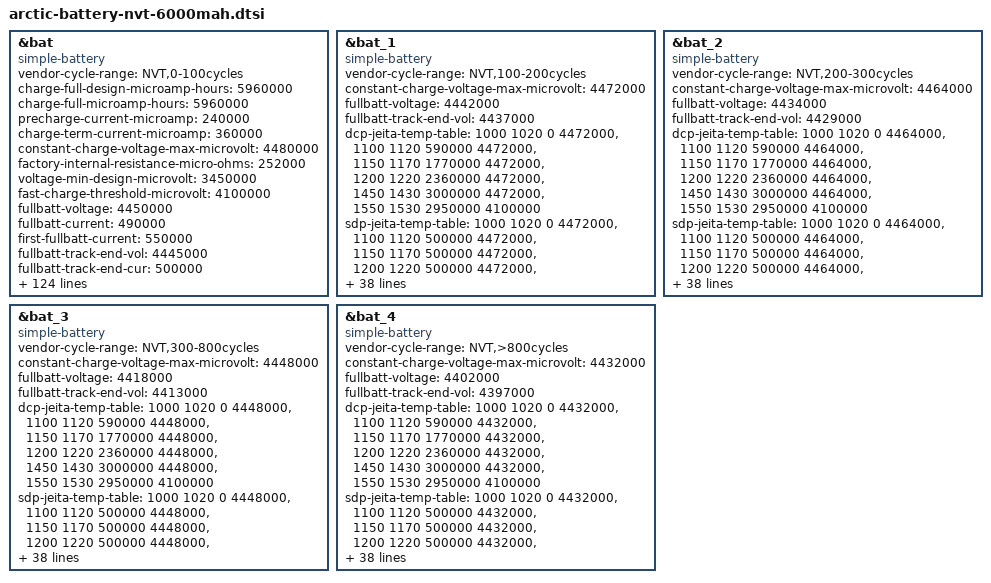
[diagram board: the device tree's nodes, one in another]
/* NVT aging 0--100 */
&bat {
	compatible = "simple-battery";
	status = "okay";
	vendor-cycle-range = "NVT,0-100cycles";
	charge-full-design-microamp-hours = <5960000>;
	charge-full-microamp-hours = <5960000>;
	precharge-current-microamp = <240000>;
	charge-term-current-microamp = <360000>;
	constant-charge-voltage-max-microvolt = <4480000>;
	factory-internal-resistance-micro-ohms = <252000>;
	voltage-min-design-microvolt = <3450000>;

	fast-charge-threshold-microvolt = <4100000>;
	fullbatt-voltage = <4450000>;
	fullbatt-current = <490000>;
	first-fullbatt-current = <550000>;
	fullbatt-track-end-vol = <4445000>;
	fullbatt-track-end-cur = <500000>;
	first-calib-voltage = <3580000>;
	first-calib-capacity = <50>;
	batt-ovp-threshold-microvolt = <4750000>;
	shutdown-voltage = <3150000>; //软件UVLO关机电压

	voltage-temp-table = <1119814 800>, <1007626 850>, <897107 900>,
				<791150 950>, <692012 1000>, <601214 1050>,
				<519546 1100>, <447188 1150>, <383853 1200>,
				<328947 1250>, <281696 1300>, <241249 1350>,
				<206756 1400>, <177412 1450>, <152480 1500>,
				<131307 1550>, <113324 1600>, <98032 1650>;

	temp-advance-fullcap-table = <50 100>, <25 100>, <10 100>, <0 100>,
		<(-10) 100>, <(-20) 100>;

	bcl-vbat-thres-celsius = <(-10)>, <0>, <10>, <25>, <45>;
	bcl-vbat-h-thres-0 = <3500>, <3400>;
	bcl-vbat-l-thres-0 = <3300>, <3200>;
	bcl-vbat-h-thres-1 = <3500>, <3400>;
	bcl-vbat-l-thres-1 = <3300>, <3200>;
	bcl-vbat-h-thres-2 = <3500>, <3400>;
	bcl-vbat-l-thres-2 = <3300>, <3200>;
	bcl-vbat-h-thres-3 = <3500>, <3400>;
	bcl-vbat-l-thres-3 = <3300>, <3200>;
	bcl-vbat-h-thres-4 = <3500>, <3400>;
	bcl-vbat-l-thres-4 = <3300>, <3200>;

	charge-sdp-current-microamp = <500000 500000>;
	charge-dcp-current-microamp = <2940000 1500000>;
	charge-cdp-current-microamp = <900000 900000>;
	charge-unknown-current-microamp = <1000000 1000000>;
	charge-fchg-current-microamp = <3000000 2000000>;
	charge-flash-current-microamp = <4900000 2700000>;
	charge-wl-bpp-current-microamp = <1000000 1000000>;
	charge-wl-epp-current-microamp = <2000000 1000000>;

	cap-calib-energy-density-ocv-table = <3400000 3690000>, <3890000 4480000>;

	dcp-jeita-temp-table = <1000 1020 0 4480000>, <1100 1120 590000 4480000>,
		<1150 1170 1770000 4480000>, <1200 1220 2360000 4480000>,
		<1450 1430 3000000 4480000>, <1550 1530 2950000 4100000>;
	sdp-jeita-temp-table = <1000 1020 0 4480000>, <1100 1120 500000 4480000>,
		<1150 1170 500000 4480000>, <1200 1220 500000 4480000>,
		<1450 1430 500000 4480000>, <1550 1530 500000 4100000>;
	cdp-jeita-temp-table = <1000 1020 0 4480000>, <1100 1120 590000 4480000>,
		<1150 1170 900000 4480000>, <1200 1220 900000 4480000>,
		<1450 1430 900000 4480000>, <1550 1530 900000 4100000>;
	unknown-jeita-temp-table = <1000 1020 0 4480000>, <1100 1120 590000 4480000>,
		<1150 1170 1000000 4480000>, <1200 1220 1000000 4480000>,
		<1450 1430 1000000 4480000>, <1550 1530 1000000 4100000>;
	fchg-jeita-temp-table = <1000 1020 0 4480000>, <1100 1120 590000 4480000>,
		<1150 1170 1770000 4480000>, <1200 1220 2360000 4480000>,
		<1450 1430 3000000 4480000>, <1550 1530 2950000 4100000>;
	flash-jeita-temp-table = <1000 1020 0 4480000>, <1100 1120 590000 4480000>,
		<1150 1170 1770000 4480000>, <1200 1220 2360000 4480000>,
		<1450 1430 3000000 4480000>, <1550 1530 2950000 4100000>;
	wl-bpp-jeita-temp-table = <1000 1020 0 4480000>, <1100 1120 500000 4480000>,
		<1150 1170 500000 4480000>, <1200 1220 500000 4480000>,
		<1450 1430 1000000 4480000>, <1550 1530 500000 4100000>;
	wl-epp-jeita-temp-table = <1000 1020 0 4480000>, <1100 1120 500000 4480000>,
		<1150 1170 500000 4480000>, <1200 1220 500000 4480000>,
		<1450 1430 2000000 4480000>, <1550 1530 500000 4100000>;


	bat-temp = <(-20)>, <(-10)>, <0>, <10>, <25>, <45>;

	/* temp-fcc */
	temp-fcc-fcc = <5344000>, <5537000>, <5769000>, <5883000>, <5960000>, <5931000>;

	/* temp-hc */
	temp-hc-hc = <20>, <20>, <20>, <10>, <10>, <10>;

	/* temp-zero-point-voltage */
	temp-zpvol-zpvol = <3430000>, <3430000>, <3430000>, <3450000>, <3450000>, <3450000>;
	/* temp-abs-zero-point-voltage */
	temp-abs-zpvol-zpvol = <3425000>, <3425000>, <3425000>, <3445000>, <3445000>, <3445000>;
	/* temp-bat-voltage */
	temp-batvol-batvol = <3570000>, <3570000>, <3570000>, <3580000>, <3580000>, <3580000>;

	/* cap-temp-ocv */
	cap-temp-ocv-cap = <100>, <99>, <98>, <97>, <96>, <95>, <94>, <93>, <92>, <91>, <90>,
			<89>, <88>, <87>, <86>, <85>, <84>, <83>, <82>, <81>, <80>,
			<79>, <78>, <77>, <76>, <75>, <74>, <73>, <72>, <71>, <70>,
			<69>, <68>, <67>, <66>, <65>, <64>, <63>, <62>, <61>, <60>,
			<59>, <58>, <57>, <56>, <55>, <54>, <53>, <52>, <51>, <50>,
			<49>, <48>, <47>, <46>, <45>, <44>, <43>, <42>, <41>, <40>,
			<39>, <38>, <37>, <36>, <35>, <34>, <33>, <32>, <31>, <30>,
			<29>, <28>, <27>, <26>, <25>, <24>, <23>, <22>, <21>, <20>,
			<19>, <18>, <17>, <16>, <15>, <14>, <13>, <12>, <11>, <10>,
			<9>, <8>, <7>, <6>, <5>, <4>, <3>, <2>, <1>, <0>;
	cap-temp-ocv-ocv = <
			/* -20 celsius */
			4428000 4394000 4369000 4350000 4332000 4317000 4302000 4288000 4274000 4261000
			4248000 4236000 4224000 4212000 4200000 4188000 4178000 4166000 4156000 4146000
			4136000 4126000 4118000 4108000 4098000 4090000 4080000 4072000 4062000 4054000
			4044000 4036000 4026000 4018000 4009000 4000000 3991000 3982000 3973000 3964000
			3956000 3946000 3938000 3929000 3920000 3912000 3904000 3896000 3888000 3880000
			3872000 3866000 3859000 3852000 3846000 3840000 3835000 3830000 3824000 3820000
			3815000 3811000 3807000 3804000 3801000 3798000 3796000 3793000 3791000 3789000
			3786000 3784000 3782000 3780000 3778000 3776000 3773000 3770000 3768000 3765000
			3762000 3758000 3756000 3752000 3748000 3742000 3737000 3732000 3725000 3717000
			3708000 3698000 3688000 3675000 3663000 3651000 3636000 3618000 3597000 3576000
			3556000
			/* -10 celsius */
			4432000 4401000 4377000 4358000 4342000 4328000 4314000 4300000 4286000 4272000
			4260000 4246000 4234000 4222000 4211000 4200000 4190000 4179000 4169000 4159000
			4149000 4140000 4131000 4121000 4112000 4102000 4093000 4084000 4074000 4065000
			4056000 4046000 4037000 4028000 4018000 4010000 4000000 3992000 3983000 3974000
			3965000 3956000 3947000 3938000 3928000 3919000 3910000 3900000 3891000 3882000
			3874000 3866000 3859000 3852000 3846000 3840000 3834000 3829000 3824000 3819000
			3815000 3810000 3806000 3803000 3800000 3796000 3794000 3791000 3789000 3787000
			3786000 3784000 3783000 3781000 3780000 3778000 3777000 3775000 3773000 3771000
			3769000 3766000 3763000 3760000 3756000 3751000 3746000 3740000 3732000 3723000
			3710000 3694000 3674000 3652000 3628000 3606000 3586000 3567000 3548000 3532000
			3518000
			/* 0 celsius */
			4428000 4398000 4376000 4358000 4341000 4326000 4312000 4298000 4284000 4272000
			4259000 4247000 4235000 4224000 4213000 4202000 4192000 4182000 4171000 4161000
			4151000 4141000 4130000 4120000 4110000 4099000 4089000 4079000 4069000 4059000
			4049000 4039000 4030000 4020000 4011000 4002000 3993000 3984000 3976000 3968000
			3960000 3951000 3942000 3934000 3925000 3914000 3904000 3893000 3883000 3872000
			3863000 3855000 3848000 3842000 3836000 3831000 3826000 3821000 3817000 3813000
			3809000 3805000 3802000 3798000 3796000 3792000 3790000 3788000 3786000 3784000
			3783000 3782000 3781000 3780000 3778000 3778000 3776000 3774000 3772000 3770000
			3768000 3764000 3760000 3755000 3750000 3743000 3735000 3725000 3712000 3693000
			3670000 3644000 3618000 3592000 3570000 3552000 3537000 3524000 3512000 3498000
			3479000
			/* 10 celsius */
			4445000 4414000 4390000 4369000 4352000 4336000 4322000 4308000 4294000 4282000
			4270000 4257000 4246000 4234000 4223000 4212000 4201000 4190000 4180000 4168000
			4158000 4147000 4136000 4126000 4115000 4104000 4094000 4082000 4072000 4062000
			4052000 4042000 4032000 4022000 4013000 4004000 3995000 3986000 3978000 3970000
			3961000 3954000 3945000 3937000 3929000 3920000 3911000 3900000 3887000 3875000
			3864000 3856000 3849000 3842000 3837000 3832000 3826000 3822000 3818000 3814000
			3810000 3806000 3803000 3800000 3797000 3794000 3792000 3789000 3787000 3786000
			3784000 3782000 3782000 3780000 3780000 3778000 3777000 3776000 3774000 3771000
			3767000 3763000 3758000 3754000 3750000 3745000 3739000 3731000 3720000 3708000
			3692000 3672000 3644000 3616000 3592000 3574000 3556000 3540000 3524000 3502000
			3462000
			/* 25 celsius */
			4441000 4411000 4386000 4366000 4349000 4334000 4319000 4306000 4292000 4280000
			4267000 4255000 4243000 4232000 4220000 4210000 4198000 4188000 4176000 4166000
			4154000 4143000 4132000 4121000 4110000 4100000 4088000 4078000 4068000 4058000
			4047000 4037000 4028000 4018000 4008000 4000000 3990000 3982000 3974000 3965000
			3957000 3949000 3942000 3934000 3926000 3918000 3908000 3896000 3882000 3870000
			3860000 3853000 3847000 3841000 3836000 3831000 3826000 3822000 3818000 3814000
			3810000 3807000 3804000 3801000 3798000 3796000 3793000 3791000 3790000 3788000
			3786000 3784000 3783000 3782000 3780000 3776000 3774000 3770000 3766000 3762000
			3758000 3754000 3752000 3748000 3744000 3740000 3733000 3726000 3720000 3712000
			3701000 3692000 3681000 3663000 3638000 3612000 3588000 3564000 3529000 3473000
			3400000
			/* 45 celsius */
			4434000 4406000 4381000 4361000 4344000 4328000 4312000 4300000 4286000 4274000
			4261000 4250000 4238000 4227000 4216000 4204000 4194000 4183000 4172000 4161000
			4150000 4140000 4128000 4118000 4106000 4096000 4086000 4074000 4064000 4054000
			4044000 4034000 4025000 4015000 4006000 3997000 3988000 3980000 3971000 3964000
			3956000 3948000 3940000 3932000 3924000 3916000 3908000 3895000 3881000 3869000
			3860000 3854000 3848000 3842000 3836000 3832000 3827000 3822000 3818000 3814000
			3810000 3807000 3803000 3800000 3797000 3794000 3792000 3789000 3787000 3785000
			3783000 3782000 3780000 3778000 3774000 3766000 3760000 3756000 3754000 3750000
			3746000 3742000 3738000 3736000 3732000 3726000 3720000 3714000 3706000 3700000
			3690000 3682000 3676000 3666000 3646000 3622000 3596000 3570000 3530000 3472000
			3400000
			>;


	/* cap-temp-resist */
	cap-temp-resist-cap = <100>, <99>, <98>, <97>, <96>, <95>, <94>, <93>, <92>, <91>, <90>,
			<89>, <88>, <87>, <86>, <85>, <84>, <83>, <82>, <81>, <80>,
			<79>, <78>, <77>, <76>, <75>, <74>, <73>, <72>, <71>, <70>,
			<69>, <68>, <67>, <66>, <65>, <64>, <63>, <62>, <61>, <60>,
			<59>, <58>, <57>, <56>, <55>, <54>, <53>, <52>, <51>, <50>,
			<49>, <48>, <47>, <46>, <45>, <44>, <43>, <42>, <41>, <40>,
			<39>, <38>, <37>, <36>, <35>, <34>, <33>, <32>, <31>, <30>,
			<29>, <28>, <27>, <26>, <25>, <24>, <23>, <22>, <21>, <20>,
			<19>, <18>, <17>, <16>, <15>, <14>, <13>, <12>, <11>, <10>,
			<9>, <8>, <7>, <6>, <5>, <4>, <3>, <2>, <1>, <0>;
	cap-temp-resist-resist = <
		  /* -20 celsius m o */
			684  684  718  724  724  724  720  715  712  708
			702  700  696  692  690  686  683  685  672  678
			676  674  672  668  668  670  670  671  670  670
			670  668  668  670  671  668  670  666  668  664
			664  665  664  661  656  662  660  658  656  656
			658  660  657  658  660  658  664  664  665  668
			672  677  682  685  691  690  698  705  712  720
			730  738  752  764  775  789  809  830  850  872
			890  914  944  978 1011 1052 1097 1146 1214 1302
			1420 1578 1806 2129 2573 2880 2880 2880 2880 2880
			2880
		  /* -10 celsius */
			349  349  358  366  369  370  369  368  366  364
			362  362  360  360  357  356  356  355  356  355
			354  355  355  354  354  355  355  355  358  358
			360  361  362  363  363  364  364  364  366  365
			364  364  362  360  357  354  350  345  340  337
			334  331  330  328  328  328  328  328  329  330
			330  331  332  334  334  336  337  338  340  344
			346  351  356  359  365  371  378  386  394  405
			416  430  445  462  482  508  538  575  620  676
			746  833  966 1227 1890 2674 2726 2726 2726 2726
			2740
		  /* 0 celsius */
			194  194  188  184  182  182  180  180  180  180
			180  178  178  179  180  180  180  180  180  180
			180  180  180  180  180  182  182  184  184  186
			186  188  189  190  191  193  194  196  198  200
			201  203  204  204  202  200  195  189  183  178
			174  172  170  168  168  168  168  168  170  169
			170  172  171  172  173  174  174  176  176  177
			179  180  182  184  186  189  192  196  199  202
			206  211  216  224  235  252  277  314  358  403
			440  469  504  574  750 1314 2437 2566 2580 2590
			2600
		  /* 10 celsius */
			116 116 116 114 112 112 112 112 112 112
			112 112 112 113 112 113 112 112 112 113
			112 112 113 112 114 114 114 114 114 116
			117 118 118 120 120 122 124 125 127 129
			130 132 134 136 138 139 138 133 125 118
			112 109 107 106 106 106 105 106 106 106
			106 106 107 108 108 108 108 109 110 110
			110 112 112 113 114 114 116 115 115 114
			114 113 113 114 116 118 122 128 137 153
			178 204 219 222 224 230 246 281 368 704
			2291
		  /* 25 celsius */
			81  81  80  80  79  79  78  78  80  79
			80  80  80  80  80  80  80  81  80  80
			80  80  80  80  80  82  81  82  82  83
			83  84  85  84  85  86  88  88  90  92
			93  94  96  98 100 102 102  97  88  82
			80  78  78  78  78  78  78  77  78  78
			78  78  78  80  80  80  81  82  82  82
			84  85  84  86  84  82  80  79  78  78
			78  78  79  80  80  80  80  82  82  83
			86  91  98 110 124 128 129 130 130 132
			144
		  /* 45 celsius */
			66 66 67 68 67 66 66 68 68 66
			68 68 67 68 68 68 68 68 68 68
			68 68 68 68 68 68 69 70 70 70
			70 71 71 71 71 72 73 73 74 75
			76 76 78 80 81 82 83 80 74 70
			70 68 68 68 68 68 68 68 68 68
			68 69 70 70 70 70 70 72 72 72
			74 74 75 76 72 68 68 68 68 70
			70 68 68 69 70 70 70 70 70 71
			71 74 75 76 80 85 86 86 84 86
			90
		>;
	cap-temp-resist-cycle = <300>, <600>;
	cap-temp-resist-ratio-0 = <
		  /* -20 celsius m o */
		  1030 1030 1030 1030 1030 1030 1030 1030 1030 1030 1040
		  1050 1050 1050 1060 1060 1060 1060 1060 1060 1060 1060
		  1060 1060 1060 1060 1060 1060 1060 1060 1060 1060 1060
		  1060 1060 1060 1060 1060 1060 1060 1060 1060 1060 1060
		  1060 1060 1060 1060 1060 1060 1060 1060 1060 1060 1060
		  1060 1060 1060 1060 1060 1060 1060 1060 1060 1050 1050
		  1050 1050 1050 1050 1050 1050 1050 1050 1050 1050 1050
		  1050 1050 1050 1050 1050 1050 1050 1050 1050 1050 1050
		  1050 1050 1050 1050 1050 1050 1050 1050 1050 1050 1050
		  1050 1050
		  /* -10 celsius */
		  1050 1050 1050 1050 1050 1050 1050 1050 1050 1050 1050
		  1050 1050 1050 1050 1050 1050 1050 1050 1050 1050 1050
		  1050 1050 1050 1050 1050 1050 1050 1050 1050 1050 1050
		  1050 1050 1050 1050 1050 1050 1050 1050 1050 1050 1050
		  1050 1050 1050 1050 1050 1050 1050 1050 1050 1050 1050
		  1050 1050 1050 1050 1050 1050 1050 1050 1050 1050 1050
		  1050 1050 1050 1050 1050 1050 1050 1050 1050 1050 1050
		  1050 1050 1050 1050 1050 1050 1050 1050 1050 1050 1050
		  1050 1050 1050 1050 1050 1050 1050 1050 1050 1050 1050
		  1050 1050
		  /* 0 celsius */
		  1160 1160 1160 1160 1160 1160 1160 1160 1170 1170 1170
		  1170 1170 1170 1170 1170 1170 1170 1170 1170 1170 1170
		  1170 1170 1170 1170 1170 1170 1170 1170 1170 1170 1170
		  1170 1170 1170 1180 1180 1180 1180 1180 1180 1180 1180
		  1180 1180 1190 1190 1190 1190 1190 1190 1190 1190 1190
		  1190 1190 1190 1190 1190 1190 1190 1190 1190 1190 1190
		  1190 1200 1200 1210 1220 1220 1220 1220 1220 1220 1230
		  1230 1230 1230 1230 1230 1230 1230 1230 1230 1230 1230
		  1230 1230 1230 1230 1250 1270 1290 1320 1350 1370 1400
		  1430 1430
		  /* 10 celsius */
		  1270 1270 1270 1270 1270 1270 1270 1270 1270 1280 1280
		  1280 1280 1290 1290 1290 1290 1290 1290 1290 1290 1290
		  1290 1300 1300 1300 1300 1300 1300 1300 1300 1300 1300
		  1300 1310 1310 1310 1310 1310 1310 1310 1310 1310 1310
		  1320 1320 1320 1320 1320 1320 1320 1320 1320 1320 1320
		  1320 1320 1330 1330 1330 1330 1330 1330 1330 1330 1330
		  1330 1330 1330 1330 1340 1340 1340 1340 1340 1340 1350
		  1360 1380 1400 1410 1430 1450 1470 1490 1500 1510 1520
		  1530 1530 1530 1530 1530 1530 1530 1530 1530 1530 1530
		  1530 1530
		  /* 25 celsius */
		  1110 1110 1110 1110 1110 1110 1110 1120 1120 1120 1130
		  1130 1140 1140 1140 1140 1140 1130 1130 1130 1130 1130
		  1130 1120 1120 1120 1120 1120 1120 1120 1120 1120 1120
		  1130 1130 1130 1130 1130 1140 1140 1140 1140 1140 1150
		  1150 1160 1160 1160 1160 1160 1160 1160 1160 1150 1150
		  1150 1150 1150 1160 1160 1160 1160 1160 1160 1150 1150
		  1150 1150 1150 1160 1160 1160 1160 1160 1160 1160 1160
		  1160 1160 1160 1160 1160 1160 1160 1160 1160 1150 1150
		  1150 1150 1150 1150 1150 1160 1160 1160 1160 1160 1160
		  1160 1160
		  /* 45 celsius */
		  1260 1260 1260 1260 1260 1260 1260 1270 1280 1290 1300
		  1300 1300 1300 1300 1300 1300 1300 1300 1300 1300 1300
		  1290 1290 1280 1270 1280 1290 1300 1310 1310 1310 1310
		  1310 1310 1310 1310 1310 1310 1310 1310 1310 1300 1290
		  1280 1270 1270 1270 1270 1270 1290 1290 1290 1290 1300
		  1310 1310 1310 1310 1310 1310 1310 1310 1300 1290 1290
		  1290 1290 1290 1300 1310 1310 1320 1320 1320 1320 1320
		  1320 1320 1320 1320 1320 1320 1320 1320 1320 1320 1310
		  1310 1310 1310 1310 1310 1310 1310 1320 1320 1320 1320
		  1320 1320
		>;

	cap-temp-resist-ratio-1 = <
		  /* -20 celsius m o */
		  1160 1160 1160 1160 1160 1160 1160 1160 1160 1170 1170
		  1180 1180 1190 1190 1190 1190 1200 1200 1210 1210 1210
		  1220 1220 1230 1230 1240 1250 1260 1270 1270 1270 1280
		  1290 1300 1310 1320 1340 1360 1380 1400 1400 1430 1460
		  1490 1520 1520 1520 1550 1590 1630 1660 1660 1690 1720
		  1750 1770 1770 1770 1770 1770 1770 1770 1770 1770 1770
		  1770 1770 1770 1770 1770 1770 1770 1770 1770 1770 1770
		  1770 1770 1770 1770 1770 1770 1770 1770 1770 1770 1770
		  1770 1770 1770 1770 1770 1770 1770 1770 1770 1770 1770
		  1770 1770
		  /* -10 celsius */
		  1180 1180 1180 1180 1180 1180 1180 1180 1170 1170 1170
		  1170 1170 1170 1170 1170 1170 1170 1170 1170 1170 1170
		  1170 1170 1170 1170 1170 1170 1170 1170 1170 1170 1170
		  1170 1170 1170 1170 1170 1170 1170 1170 1170 1170 1190
		  1190 1190 1190 1190 1200 1200 1200 1200 1200 1210 1210
		  1210 1210 1210 1210 1220 1240 1250 1270 1290 1290 1290
		  1290 1290 1290 1290 1300 1310 1320 1330 1340 1350 1350
		  1350 1370 1390 1410 1420 1440 1440 1460 1480 1500 1530
		  1550 1570 1590 1610 1620 1620 1620 1620 1620 1620 1620
		  1620 1620
		  /* 0 celsius */
		  1420 1420 1420 1420 1420 1420 1420 1420 1410 1410 1410
		  1410 1410 1410 1410 1410 1410 1410 1410 1410 1410 1410
		  1400 1400 1400 1400 1400 1400 1400 1400 1400 1400 1400
		  1400 1400 1400 1400 1400 1400 1400 1400 1400 1410 1410
		  1410 1410 1420 1420 1420 1420 1420 1420 1420 1420 1420
		  1420 1430 1430 1430 1430 1430 1430 1450 1450 1450 1450
		  1450 1450 1500 1500 1500 1500 1500 1500 1530 1530 1530
		  1530 1530 1530 1550 1550 1550 1550 1610 1610 1610 1610
		  1650 1700 1750 1800 1850 1900 1900 1900 1900 1900 1900
		  1900 1900
		  /* 10 celsius */
		  1400 1400 1400 1400 1400 1400 1400 1400 1400 1420 1420
		  1420 1420 1420 1420 1420 1420 1420 1420 1420 1420 1420
		  1420 1420 1420 1420 1420 1420 1410 1410 1410 1410 1410
		  1410 1410 1410 1410 1410 1410 1410 1410 1410 1410 1410
		  1410 1420 1420 1420 1420 1430 1430 1430 1430 1430 1420
		  1430 1430 1430 1430 1430 1430 1430 1430 1430 1430 1430
		  1430 1430 1430 1430 1470 1470 1470 1470 1470 1530 1530
		  1530 1530 1530 1590 1590 1590 1590 1630 1680 1710 1710
		  1780 1840 1900 1950 2000 2050 2100 2150 2200 2250 2250
		  2250 2250
		  /* 25 celsius */
		  1320 1320 1320 1320 1320 1320 1320 1320 1320 1320 1320
		  1320 1310 1310 1310 1310 1310 1310 1300 1300 1300 1300
		  1300 1290 1290 1290 1290 1290 1280 1280 1280 1280 1280
		  1280 1280 1280 1280 1280 1280 1280 1280 1280 1280 1290
		  1290 1300 1310 1310 1310 1310 1310 1310 1310 1310 1310
		  1310 1310 1310 1310 1310 1310 1310 1310 1310 1310 1310
		  1310 1310 1310 1310 1310 1310 1310 1320 1330 1340 1350
		  1350 1360 1360 1360 1360 1360 1370 1370 1370 1380 1390
		  1400 1410 1420 1430 1450 1460 1460 1460 1460 1460 1460
		  1460 1460
		  /* 45 celsius */
		  1298 1298 1298 1298 1298 1298 1298 1308 1318 1329 1339
		  1339 1339 1339 1339 1339 1339 1339 1339 1339 1339 1339
		  1329 1329 1318 1308 1318 1329 1339 1349 1349 1349 1349
		  1349 1349 1349 1349 1349 1349 1349 1349 1349 1339 1329
		  1318 1308 1308 1308 1308 1308 1329 1329 1329 1329 1339
		  1349 1349 1349 1349 1349 1349 1349 1349 1339 1329 1329
		  1329 1329 1329 1339 1349 1349 1360 1360 1360 1360 1360
		  1360 1360 1360 1360 1360 1360 1360 1360 1360 1360 1349
		  1349 1349 1349 1349 1349 1349 1349 1360 1360 1360 1360
		  1360 1360
		>;
};

/* NVT aging 100--200 */
&bat_1 {
	compatible = "simple-battery";
	status = "okay";
	vendor-cycle-range = "NVT,100-200cycles";
	constant-charge-voltage-max-microvolt = <4472000>;
	fullbatt-voltage = <4442000>;
	fullbatt-track-end-vol = <4437000>;

	dcp-jeita-temp-table = <1000 1020 0 4472000>, <1100 1120 590000 4472000>,
		<1150 1170 1770000 4472000>, <1200 1220 2360000 4472000>,
		<1450 1430 3000000 4472000>, <1550 1530 2950000 4100000>;
	sdp-jeita-temp-table = <1000 1020 0 4472000>, <1100 1120 500000 4472000>,
		<1150 1170 500000 4472000>, <1200 1220 500000 4472000>,
		<1450 1430 500000 4472000>, <1550 1530 500000 4100000>;
	cdp-jeita-temp-table = <1000 1020 0 4472000>, <1100 1120 590000 4472000>,
		<1150 1170 900000 4472000>, <1200 1220 900000 4472000>,
		<1450 1430 900000 4472000>, <1550 1530 900000 4100000>;
	unknown-jeita-temp-table = <1000 1020 0 4472000>, <1100 1120 590000 4472000>,
		<1150 1170 1000000 4472000>, <1200 1220 1000000 4472000>,
		<1450 1430 1000000 4472000>, <1550 1530 1000000 4100000>;
	fchg-jeita-temp-table = <1000 1020 0 4472000>, <1100 1120 590000 4472000>,
		<1150 1170 1770000 4472000>, <1200 1220 2360000 4472000>,
		<1450 1430 3000000 4472000>, <1550 1530 2950000 4100000>;
	flash-jeita-temp-table = <1000 1020 0 4472000>, <1100 1120 590000 4472000>,
		<1150 1170 1770000 4472000>, <1200 1220 2360000 4472000>,
		<1450 1430 3000000 4472000>, <1550 1530 2950000 4100000>;
	wl-bpp-jeita-temp-table = <1000 1020 0 4472000>, <1100 1120 500000 4472000>,
		<1150 1170 500000 4472000>, <1200 1220 500000 4472000>,
		<1450 1430 1000000 4472000>, <1550 1530 500000 4100000>;
	wl-epp-jeita-temp-table = <1000 1020 0 4472000>, <1100 1120 500000 4472000>,
		<1150 1170 500000 4472000>, <1200 1220 500000 4472000>,
		<1450 1430 2000000 4472000>, <1550 1530 500000 4100000>;
};

/* NVT aging 200--300 */
&bat_2 {
	compatible = "simple-battery";
	status = "okay";
	vendor-cycle-range = "NVT,200-300cycles";
	constant-charge-voltage-max-microvolt = <4464000>;
	fullbatt-voltage = <4434000>;
	fullbatt-track-end-vol = <4429000>;

	dcp-jeita-temp-table = <1000 1020 0 4464000>, <1100 1120 590000 4464000>,
		<1150 1170 1770000 4464000>, <1200 1220 2360000 4464000>,
		<1450 1430 3000000 4464000>, <1550 1530 2950000 4100000>;
	sdp-jeita-temp-table = <1000 1020 0 4464000>, <1100 1120 500000 4464000>,
		<1150 1170 500000 4464000>, <1200 1220 500000 4464000>,
		<1450 1430 500000 4464000>, <1550 1530 500000 4100000>;
	cdp-jeita-temp-table = <1000 1020 0 4464000>, <1100 1120 590000 4464000>,
		<1150 1170 900000 4464000>, <1200 1220 900000 4464000>,
		<1450 1430 900000 4464000>, <1550 1530 900000 4100000>;
	unknown-jeita-temp-table = <1000 1020 0 4464000>, <1100 1120 590000 4464000>,
		<1150 1170 1000000 4464000>, <1200 1220 1000000 4464000>,
		<1450 1430 1000000 4464000>, <1550 1530 1000000 4100000>;
	fchg-jeita-temp-table = <1000 1020 0 4464000>, <1100 1120 590000 4464000>,
		<1150 1170 1770000 4464000>, <1200 1220 2360000 4464000>,
		<1450 1430 3000000 4464000>, <1550 1530 2950000 4100000>;
	flash-jeita-temp-table = <1000 1020 0 4464000>, <1100 1120 590000 4464000>,
		<1150 1170 1770000 4464000>, <1200 1220 2360000 4464000>,
		<1450 1430 3000000 4464000>, <1550 1530 2950000 4100000>;
	wl-bpp-jeita-temp-table = <1000 1020 0 4464000>, <1100 1120 500000 4464000>,
		<1150 1170 500000 4464000>, <1200 1220 500000 4464000>,
		<1450 1430 1000000 4464000>, <1550 1530 500000 4100000>;
	wl-epp-jeita-temp-table = <1000 1020 0 4464000>, <1100 1120 500000 4464000>,
		<1150 1170 500000 4464000>, <1200 1220 500000 4464000>,
		<1450 1430 2000000 4464000>, <1550 1530 500000 4100000>;
};

/* NVT aging 300--800 */
&bat_3 {
	compatible = "simple-battery";
	status = "okay";
	vendor-cycle-range = "NVT,300-800cycles";
	constant-charge-voltage-max-microvolt = <4448000>;
	fullbatt-voltage = <4418000>;
	fullbatt-track-end-vol = <4413000>;

	dcp-jeita-temp-table = <1000 1020 0 4448000>, <1100 1120 590000 4448000>,
		<1150 1170 1770000 4448000>, <1200 1220 2360000 4448000>,
		<1450 1430 3000000 4448000>, <1550 1530 2950000 4100000>;
	sdp-jeita-temp-table = <1000 1020 0 4448000>, <1100 1120 500000 4448000>,
		<1150 1170 500000 4448000>, <1200 1220 500000 4448000>,
		<1450 1430 500000 4448000>, <1550 1530 500000 4100000>;
	cdp-jeita-temp-table = <1000 1020 0 4448000>, <1100 1120 590000 4448000>,
		<1150 1170 900000 4448000>, <1200 1220 900000 4448000>,
		<1450 1430 900000 4448000>, <1550 1530 900000 4100000>;
	unknown-jeita-temp-table = <1000 1020 0 4448000>, <1100 1120 590000 4448000>,
		<1150 1170 1000000 4448000>, <1200 1220 1000000 4448000>,
		<1450 1430 1000000 4448000>, <1550 1530 1000000 4100000>;
	fchg-jeita-temp-table = <1000 1020 0 4448000>, <1100 1120 590000 4448000>,
		<1150 1170 1770000 4448000>, <1200 1220 2360000 4448000>,
		<1450 1430 3000000 4448000>, <1550 1530 2950000 4100000>;
	flash-jeita-temp-table = <1000 1020 0 4448000>, <1100 1120 590000 4448000>,
		<1150 1170 1770000 4448000>, <1200 1220 2360000 4448000>,
		<1450 1430 3000000 4448000>, <1550 1530 2950000 4100000>;
	wl-bpp-jeita-temp-table = <1000 1020 0 4448000>, <1100 1120 500000 4448000>,
		<1150 1170 500000 4448000>, <1200 1220 500000 4448000>,
		<1450 1430 1000000 4448000>, <1550 1530 500000 4100000>;
	wl-epp-jeita-temp-table = <1000 1020 0 4448000>, <1100 1120 500000 4448000>,
		<1150 1170 500000 4448000>, <1200 1220 500000 4448000>,
		<1450 1430 2000000 4448000>, <1550 1530 500000 4100000>;
};

/* NVT aging > 800 */
&bat_4 {
	compatible = "simple-battery";
	status = "okay";
	vendor-cycle-range = "NVT,>800cycles";
	constant-charge-voltage-max-microvolt = <4432000>;
	fullbatt-voltage = <4402000>;
	fullbatt-track-end-vol = <4397000>;

	dcp-jeita-temp-table = <1000 1020 0 4432000>, <1100 1120 590000 4432000>,
		<1150 1170 1770000 4432000>, <1200 1220 2360000 4432000>,
		<1450 1430 3000000 4432000>, <1550 1530 2950000 4100000>;
	sdp-jeita-temp-table = <1000 1020 0 4432000>, <1100 1120 500000 4432000>,
		<1150 1170 500000 4432000>, <1200 1220 500000 4432000>,
		<1450 1430 500000 4432000>, <1550 1530 500000 4100000>;
	cdp-jeita-temp-table = <1000 1020 0 4432000>, <1100 1120 590000 4432000>,
		<1150 1170 900000 4432000>, <1200 1220 900000 4432000>,
		<1450 1430 900000 4432000>, <1550 1530 900000 4100000>;
	unknown-jeita-temp-table = <1000 1020 0 4432000>, <1100 1120 590000 4432000>,
		<1150 1170 1000000 4432000>, <1200 1220 1000000 4432000>,
		<1450 1430 1000000 4432000>, <1550 1530 1000000 4100000>;
	fchg-jeita-temp-table = <1000 1020 0 4432000>, <1100 1120 590000 4432000>,
		<1150 1170 1770000 4432000>, <1200 1220 2360000 4432000>,
		<1450 1430 3000000 4432000>, <1550 1530 2950000 4100000>;
	flash-jeita-temp-table = <1000 1020 0 4432000>, <1100 1120 590000 4432000>,
		<1150 1170 1770000 4432000>, <1200 1220 2360000 4432000>,
		<1450 1430 3000000 4432000>, <1550 1530 2950000 4100000>;
	wl-bpp-jeita-temp-table = <1000 1020 0 4432000>, <1100 1120 500000 4432000>,
		<1150 1170 500000 4432000>, <1200 1220 500000 4432000>,
		<1450 1430 1000000 4432000>, <1550 1530 500000 4100000>;
	wl-epp-jeita-temp-table = <1000 1020 0 4432000>, <1100 1120 500000 4432000>,
		<1150 1170 500000 4432000>, <1200 1220 500000 4432000>,
		<1450 1430 2000000 4432000>, <1550 1530 500000 4100000>;
};
